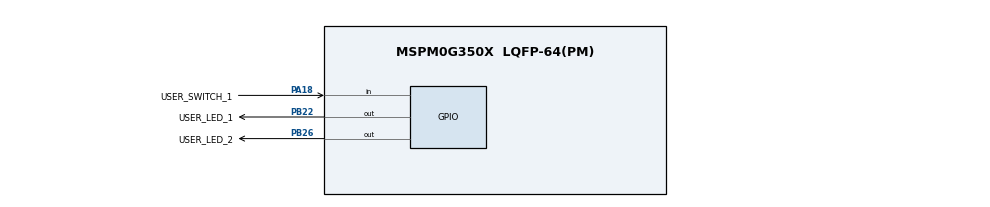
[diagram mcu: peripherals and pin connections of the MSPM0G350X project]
// @cliArgs --device "MSPM0G350X" --package "LQFP-64(PM)" --part "Default"
// @cliArgs --board /ti/boards/LP_MSPM0G3507 --rtos nortos

/**
 * Import the modules used in this configuration.
 */
const GPIO   = scripting.addModule("/ti/driverlib/GPIO", {}, false);
const GPIO1  = GPIO.addInstance();
const GPIO2  = GPIO.addInstance();
const GPIO3  = GPIO.addInstance();
const SYSCTL = scripting.addModule("/ti/driverlib/SYSCTL");

/**
 * Write custom configuration values to the imported modules.
 */
GPIO1.$name                         = "GPIO_LEDS";
GPIO1.port                          = "PORTB";
GPIO1.associatedPins.create(2);
GPIO1.associatedPins[0].$name       = "USER_LED_1";
GPIO1.associatedPins[0].assignedPin = "22";
GPIO1.associatedPins[0].pin.$assign = "PB22";
GPIO1.associatedPins[1].$name       = "USER_LED_2";
GPIO1.associatedPins[1].assignedPin = "26";
GPIO1.associatedPins[1].pin.$assign = "PB26";

const Board           = scripting.addModule("/ti/driverlib/Board", {}, false);
Board.configureUnused = true;

GPIO2.$name                         = "GPIO_SWITCH";
GPIO2.port                          = "PORTA";
GPIO2.associatedPins[0].assignedPin = "18";
GPIO2.associatedPins[0].direction   = "INPUT";
GPIO2.associatedPins[0].$name       = "USER_SWITCH_1";
GPIO2.associatedPins[0].polarity    = "RISE";
GPIO2.associatedPins[0].wakeupLogic = "ON_1";
GPIO2.associatedPins[0].pin.$assign = "PA18";

GPIO3.$name                              = "GPIO_INPUT";
GPIO3.port                               = "PORTB";
GPIO3.associatedPins.create(2);
GPIO3.associatedPins[0].$name            = "CONFIG_0";
GPIO3.associatedPins[0].direction        = "INPUT";
GPIO3.associatedPins[0].internalResistor = "PULL_UP";
GPIO3.associatedPins[0].assignedPin      = "17";
GPIO3.associatedPins[1].$name            = "CONFIG_1";
GPIO3.associatedPins[1].assignedPin      = "12";
GPIO3.associatedPins[1].direction        = "INPUT";
GPIO3.associatedPins[1].internalResistor = "PULL_UP";

SYSCTL.forceDefaultClkConfig = true;
SYSCTL.clockTreeEn  = true;
